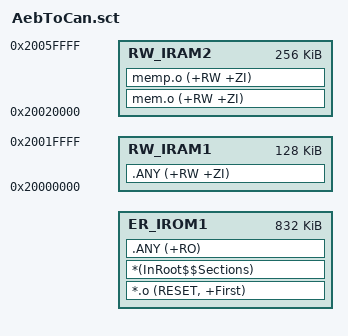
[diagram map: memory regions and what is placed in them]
#! armcc -E
#include "../../App/bootloaderDef.h"

LR_IROM1 (APP_START_ADDR) 0x000D0000  {    ; load region size_region
  ER_IROM1 (APP_START_ADDR) 0x000D0000  {  ; load address = execution address
   *.o (RESET, +First)
   *(InRoot$$Sections)
   .ANY (+RO)
  }
  RW_IRAM1 0x20000000 0x00020000  {  ; RW data
   .ANY (+RW +ZI)
  }
  RW_IRAM2 0x20020000 0x00040000  {  ; RW data
   mem.o (+RW +ZI)
   memp.o (+RW +ZI)
  }
}

